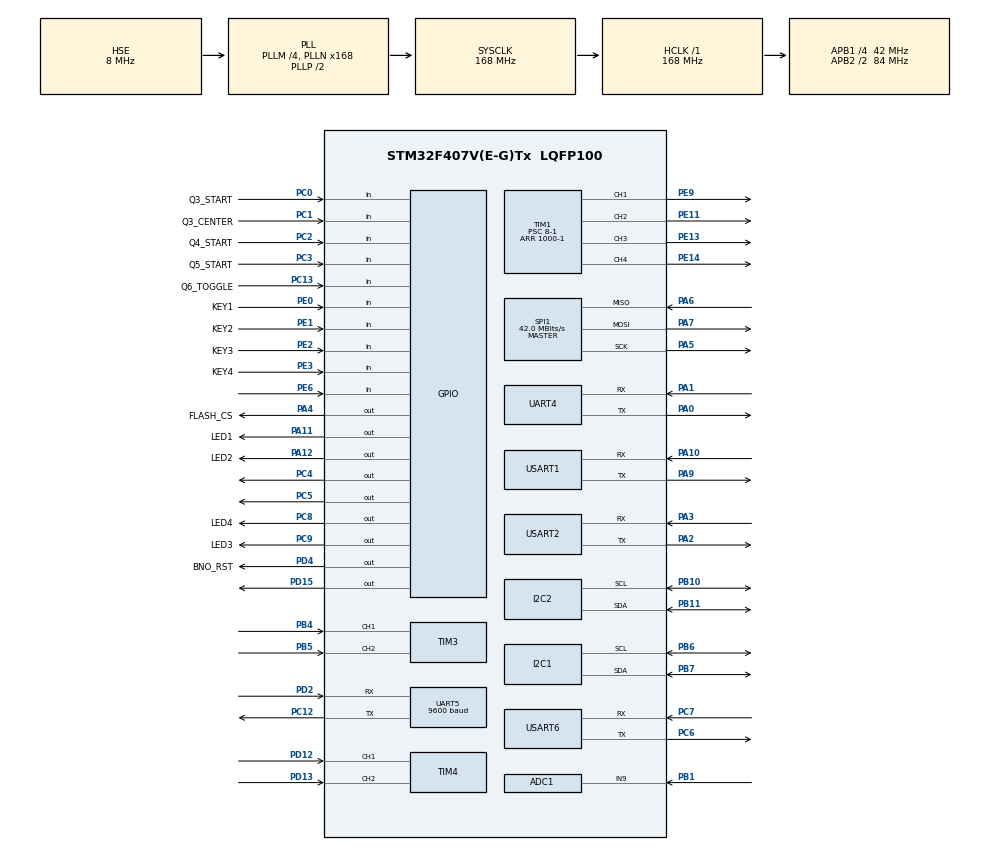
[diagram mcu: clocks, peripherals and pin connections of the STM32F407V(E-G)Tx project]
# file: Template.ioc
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ADC1.Channel-1\#ChannelRegularConversion=ADC_CHANNEL_9
ADC1.NbrOfConversionFlag=1
ADC1.Rank-1\#ChannelRegularConversion=1
ADC1.SamplingTime-1\#ChannelRegularConversion=ADC_SAMPLETIME_144CYCLES
ADC1.master=1
Dma.Request0=UART5_RX
Dma.Request1=USART1_RX
Dma.Request2=USART6_RX
Dma.Request3=UART4_RX
Dma.Request4=USART2_RX
Dma.UART4_RX.3.Direction=DMA_PERIPH_TO_MEMORY
Dma.UART4_RX.3.FIFOMode=DMA_FIFOMODE_DISABLE
Dma.UART4_RX.3.Instance=DMA1_Stream2
Dma.UART4_RX.3.MemDataAlignment=DMA_MDATAALIGN_BYTE
Dma.UART4_RX.3.MemInc=DMA_MINC_ENABLE
Dma.UART4_RX.3.Mode=DMA_NORMAL
Dma.UART4_RX.3.PeriphDataAlignment=DMA_PDATAALIGN_BYTE
Dma.UART4_RX.3.PeriphInc=DMA_PINC_DISABLE
Dma.UART4_RX.3.Priority=DMA_PRIORITY_LOW
Dma.UART5_RX.0.Direction=DMA_PERIPH_TO_MEMORY
Dma.UART5_RX.0.FIFOMode=DMA_FIFOMODE_DISABLE
Dma.UART5_RX.0.Instance=DMA1_Stream0
Dma.UART5_RX.0.MemDataAlignment=DMA_MDATAALIGN_BYTE
Dma.UART5_RX.0.MemInc=DMA_MINC_ENABLE
Dma.UART5_RX.0.Mode=DMA_NORMAL
Dma.UART5_RX.0.PeriphDataAlignment=DMA_PDATAALIGN_BYTE
Dma.UART5_RX.0.PeriphInc=DMA_PINC_DISABLE
Dma.UART5_RX.0.Priority=DMA_PRIORITY_LOW
Dma.USART1_RX.1.Direction=DMA_PERIPH_TO_MEMORY
Dma.USART1_RX.1.FIFOMode=DMA_FIFOMODE_DISABLE
Dma.USART1_RX.1.Instance=DMA2_Stream2
Dma.USART1_RX.1.MemDataAlignment=DMA_MDATAALIGN_BYTE
Dma.USART1_RX.1.MemInc=DMA_MINC_ENABLE
Dma.USART1_RX.1.Mode=DMA_NORMAL
Dma.USART1_RX.1.PeriphDataAlignment=DMA_PDATAALIGN_BYTE
Dma.USART1_RX.1.PeriphInc=DMA_PINC_DISABLE
Dma.USART1_RX.1.Priority=DMA_PRIORITY_LOW
Dma.USART2_RX.4.Direction=DMA_PERIPH_TO_MEMORY
Dma.USART2_RX.4.FIFOMode=DMA_FIFOMODE_DISABLE
Dma.USART2_RX.4.Instance=DMA1_Stream5
Dma.USART2_RX.4.MemDataAlignment=DMA_MDATAALIGN_BYTE
Dma.USART2_RX.4.MemInc=DMA_MINC_ENABLE
Dma.USART2_RX.4.Mode=DMA_NORMAL
Dma.USART2_RX.4.PeriphDataAlignment=DMA_PDATAALIGN_BYTE
Dma.USART2_RX.4.PeriphInc=DMA_PINC_DISABLE
Dma.USART2_RX.4.Priority=DMA_PRIORITY_LOW
Dma.USART6_RX.2.Direction=DMA_PERIPH_TO_MEMORY
Dma.USART6_RX.2.FIFOMode=DMA_FIFOMODE_DISABLE
Dma.USART6_RX.2.Instance=DMA2_Stream1
Dma.USART6_RX.2.MemDataAlignment=DMA_MDATAALIGN_BYTE
Dma.USART6_RX.2.MemInc=DMA_MINC_ENABLE
Dma.USART6_RX.2.Mode=DMA_NORMAL
Dma.USART6_RX.2.PeriphDataAlignment=DMA_PDATAALIGN_BYTE
Dma.USART6_RX.2.PeriphInc=DMA_PINC_DISABLE
Dma.USART6_RX.2.Priority=DMA_PRIORITY_LOW
I2C2.I2C_Mode=I2C_Standard
Mcu.Family=STM32F4
Mcu.Name=STM32F407V(E-G)Tx
Mcu.Package=LQFP100
NVIC.DMA1_Stream0_IRQn=true\:0\:0\:false\:false\:true\:false\:true\:true
NVIC.DMA1_Stream2_IRQn=true\:0\:0\:false\:false\:true\:false\:true\:true
NVIC.DMA1_Stream5_IRQn=true\:0\:0\:false\:false\:true\:false\:true\:true
NVIC.DMA2_Stream1_IRQn=true\:1\:0\:true\:false\:true\:false\:true\:true
NVIC.DMA2_Stream2_IRQn=true\:1\:0\:true\:false\:true\:false\:true\:true
NVIC.PriorityGroup=NVIC_PRIORITYGROUP_4
NVIC.TIM2_IRQn=true\:1\:0\:true\:false\:true\:true\:true\:true
NVIC.UART4_IRQn=true\:1\:0\:true\:false\:true\:true\:true\:true
NVIC.UART5_IRQn=true\:1\:0\:true\:false\:true\:true\:true\:true
NVIC.USART1_IRQn=true\:1\:0\:true\:false\:true\:true\:true\:true
NVIC.USART2_IRQn=true\:1\:0\:true\:false\:true\:true\:true\:true
NVIC.USART6_IRQn=true\:1\:0\:true\:false\:true\:true\:true\:true
PA0.Mode=Asynchronous
PA0.Signal=UART4_TX
PA1.Mode=Asynchronous
PA1.Signal=UART4_RX
PA10.Mode=Asynchronous
PA10.Signal=USART1_RX
PA11.GPIO_Label=LED1
PA11.PinState=GPIO_PIN_SET
PA11.Signal=GPIO_Output
PA12.GPIO_Label=LED2
PA12.PinState=GPIO_PIN_SET
PA12.Signal=GPIO_Output
PA13.Mode=Serial_Wire
PA13.Signal=SYS_JTMS-SWDIO
PA14.Mode=Serial_Wire
PA14.Signal=SYS_JTCK-SWCLK
PA2.Mode=Asynchronous
PA2.Signal=USART2_TX
PA3.Mode=Asynchronous
PA3.Signal=USART2_RX
PA4.GPIO_Label=FLASH_CS
PA4.PinState=GPIO_PIN_SET
PA4.Signal=GPIO_Output
PA5.Mode=Full_Duplex_Master
PA5.Signal=SPI1_SCK
PA6.Mode=Full_Duplex_Master
PA6.Signal=SPI1_MISO
PA7.Mode=Full_Duplex_Master
PA7.Signal=SPI1_MOSI
PA9.Mode=Asynchronous
PA9.Signal=USART1_TX
PB1.Signal=ADCx_IN9
PB10.Mode=I2C
PB10.Signal=I2C2_SCL
PB11.Mode=I2C
PB11.Signal=I2C2_SDA
PB4.Signal=S_TIM3_CH1
PB5.Signal=S_TIM3_CH2
PB6.Mode=I2C
PB6.Signal=I2C1_SCL
PB7.Mode=I2C
PB7.Signal=I2C1_SDA
PC0.GPIO_Label=Q3_START
PC0.GPIO_PuPd=GPIO_PULLUP
PC0.Signal=GPIO_Input
PC1.GPIO_Label=Q3_CENTER
PC1.GPIO_PuPd=GPIO_PULLUP
PC1.Signal=GPIO_Input
PC12.Mode=Asynchronous
PC12.Signal=UART5_TX
PC13-ANTI_TAMP.GPIO_Label=Q6_TOGGLE
PC13-ANTI_TAMP.GPIO_PuPd=GPIO_PULLUP
PC13-ANTI_TAMP.Signal=GPIO_Input
PC14-OSC32_IN.Mode=LSE-External-Oscillator
PC14-OSC32_IN.Signal=RCC_OSC32_IN
PC15-OSC32_OUT.Mode=LSE-External-Oscillator
PC15-OSC32_OUT.Signal=RCC_OSC32_OUT
PC2.GPIO_Label=Q4_START
PC2.GPIO_PuPd=GPIO_PULLUP
PC2.Signal=GPIO_Input
PC3.GPIO_Label=Q5_START
PC3.GPIO_PuPd=GPIO_PULLUP
PC3.Signal=GPIO_Input
PC4.PinState=GPIO_PIN_RESET
PC4.Signal=GPIO_Output
PC5.PinState=GPIO_PIN_RESET
PC5.Signal=GPIO_Output
PC6.Mode=Asynchronous
PC6.Signal=USART6_TX
PC7.Mode=Asynchronous
PC7.Signal=USART6_RX
PC8.GPIO_Label=LED4
PC8.PinState=GPIO_PIN_SET
PC8.Signal=GPIO_Output
PC9.GPIO_Label=LED3
PC9.PinState=GPIO_PIN_SET
PC9.Signal=GPIO_Output
PD12.Signal=S_TIM4_CH1
PD13.Signal=S_TIM4_CH2
PD15.PinState=GPIO_PIN_RESET
PD15.Signal=GPIO_Output
PD2.Mode=Asynchronous
PD2.Signal=UART5_RX
PD4.GPIO_Label=BNO_RST
PD4.Signal=GPIO_Output
PE0.GPIO_Label=KEY1
PE0.Signal=GPIO_Input
PE1.GPIO_Label=KEY2
PE1.Signal=GPIO_Input
PE11.Signal=S_TIM1_CH2
PE13.Signal=S_TIM1_CH3
PE14.Signal=S_TIM1_CH4
PE2.GPIO_Label=KEY3
PE2.Signal=GPIO_Input
PE3.GPIO_Label=KEY4
PE3.Signal=GPIO_Input
PE6.Signal=GPIO_Input
PE9.Signal=S_TIM1_CH1
PH0-OSC_IN.Mode=HSE-External-Oscillator
PH0-OSC_IN.Signal=RCC_OSC_IN
PH1-OSC_OUT.Mode=HSE-External-Oscillator
PH1-OSC_OUT.Signal=RCC_OSC_OUT
ProjectManager.HeapSize=0x1200
ProjectManager.StackSize=0x1000
ProjectManager.TargetToolchain=MDK-ARM V5.32
RCC.48MHZClocksFreq_Value=84000000
RCC.AHBFreq_Value=168000000
RCC.APB1CLKDivider=RCC_HCLK_DIV4
RCC.APB1Freq_Value=42000000
RCC.APB1TimFreq_Value=84000000
RCC.APB2CLKDivider=RCC_HCLK_DIV2
RCC.APB2Freq_Value=84000000
RCC.APB2TimFreq_Value=168000000
RCC.CortexFreq_Value=168000000
RCC.HCLKFreq_Value=168000000
RCC.HSE_VALUE=8000000
RCC.HSI_VALUE=16000000
RCC.PLLM=4
RCC.PLLN=168
RCC.PLLSourceVirtual=RCC_PLLSOURCE_HSE
RCC.SYSCLKFreq_VALUE=168000000
RCC.SYSCLKSource=RCC_SYSCLKSOURCE_PLLCLK
RCC.VCOOutputFreq_Value=336000000
SH.ADCx_IN9.0=ADC1_IN9,IN9
SH.S_TIM1_CH1.0=TIM1_CH1,PWM Generation1 CH1
SH.S_TIM1_CH2.0=TIM1_CH2,PWM Generation2 CH2
SH.S_TIM1_CH3.0=TIM1_CH3,PWM Generation3 CH3
SH.S_TIM1_CH4.0=TIM1_CH4,PWM Generation4 CH4
SH.S_TIM3_CH1.0=TIM3_CH1,Encoder_Interface
SH.S_TIM3_CH2.0=TIM3_CH2,Encoder_Interface
SH.S_TIM4_CH1.0=TIM4_CH1,Encoder_Interface
SH.S_TIM4_CH2.0=TIM4_CH2,Encoder_Interface
SPI1.BaudRatePrescaler=SPI_BAUDRATEPRESCALER_2
SPI1.CLKPhase=SPI_PHASE_2EDGE
SPI1.CLKPolarity=SPI_POLARITY_HIGH
SPI1.CalculateBaudRate=42.0 MBits/s
SPI1.Direction=SPI_DIRECTION_2LINES
SPI1.Mode=SPI_MODE_MASTER
SPI1.VirtualType=VM_MASTER
TIM1.Channel-PWM\ Generation1\ CH1=TIM_CHANNEL_1
TIM1.Channel-PWM\ Generation2\ CH2=TIM_CHANNEL_2
TIM1.Channel-PWM\ Generation3\ CH3=TIM_CHANNEL_3
TIM1.Channel-PWM\ Generation4\ CH4=TIM_CHANNEL_4
TIM1.Period=1000-1
TIM1.Prescaler=8-1
TIM2.Period=1000-1
TIM2.Prescaler=84-1
TIM3.EncoderMode=TIM_ENCODERMODE_TI12
TIM3.IC1Filter=8
TIM3.IC2Filter=8
TIM4.EncoderMode=TIM_ENCODERMODE_TI12
TIM4.IC1Filter=8
TIM4.IC2Filter=8
UART4.VirtualMode=Asynchronous
UART5.BaudRate=9600
UART5.VirtualMode=Asynchronous
USART1.VirtualMode=VM_ASYNC
USART2.VirtualMode=VM_ASYNC
USART6.VirtualMode=VM_ASYNC
VP_TIM1_VS_ClockSourceINT.Mode=Internal
VP_TIM2_VS_ClockSourceINT.Mode=Internal
board=custom

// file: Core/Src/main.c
/* USER CODE BEGIN Header */
/**
  ******************************************************************************
  * @file           : main.c
  * @brief          : Main program body
  ******************************************************************************
  * @attention
  *
  * Copyright (c) 2025 STMicroelectronics.
  * All rights reserved.
  *
  * This software is licensed under terms that can be found in the LICENSE file
  * in the root directory of this software component.
  * If no LICENSE file comes with this software, it is provided AS-IS.
  *
  ******************************************************************************
  */
/* USER CODE END Header */
#include "main.h"
#include "adc.h"
#include "dma.h"
#include "i2c.h"
#include "spi.h"
#include "tim.h"
#include "usart.h"
#include "gpio.h"

/* USER CODE BEGIN Includes */
#include "MyDefine.h"
/* USER CODE END Includes */

void SystemClock_Config(void);

int main(void)
{

  /* MCU Configuration--------------------------------------------------------*/

  /* Reset of all peripherals, Initializes the Flash interface and the Systick. */
  HAL_Init();

  /* Configure the system clock */
  SystemClock_Config();

  /* Initialize all configured peripherals */
  MX_GPIO_Init();
  MX_DMA_Init();
  MX_UART5_Init();
  MX_I2C2_Init();
  MX_TIM1_Init();
  MX_TIM3_Init();
  MX_TIM4_Init();
  MX_TIM2_Init();
  MX_I2C1_Init();
  MX_USART1_UART_Init();
  MX_USART6_UART_Init();
  MX_UART4_Init();
  MX_USART2_UART_Init();
  MX_SPI1_Init();
  MX_ADC1_Init();
  /* USER CODE BEGIN 2 */
  Scheduler_Init();
	System_Init();
  /* USER CODE END 2 */

  /* Infinite loop */
  /* USER CODE BEGIN WHILE */
  while (1)
  {
    Scheduler_Run();
    /* USER CODE END WHILE */

    /* USER CODE BEGIN 3 */
//    Uart_Printf(DEBUG_UART,
//                "Euler Roll=%.2f Pitch=%.2f Yaw=%.2f\r\n",
//                euler_angles.roll,
//                euler_angles.pitch,
//                euler_angles.yaw);
//    HAL_Delay(200);
//		Uart_Printf(&huart5,"{left}%f,%f\r\n",pid_speed_left.target,pid_speed_left.current);
//		Uart_Printf(&huart5,"{right}%f,%f\r\n",pid_speed_right.target,pid_speed_right.current);
  }
  /* USER CODE END 3 */
}

void SystemClock_Config(void)
{
  RCC_OscInitTypeDef RCC_OscInitStruct = {0};
  RCC_ClkInitTypeDef RCC_ClkInitStruct = {0};

  /** Configure the main internal regulator output voltage
  */
  __HAL_RCC_PWR_CLK_ENABLE();
  __HAL_PWR_VOLTAGESCALING_CONFIG(PWR_REGULATOR_VOLTAGE_SCALE1);

  /** Initializes the RCC Oscillators according to the specified parameters
  * in the RCC_OscInitTypeDef structure.
  */
  RCC_OscInitStruct.OscillatorType = RCC_OSCILLATORTYPE_HSE;
  RCC_OscInitStruct.HSEState = RCC_HSE_ON;
  RCC_OscInitStruct.PLL.PLLState = RCC_PLL_ON;
  RCC_OscInitStruct.PLL.PLLSource = RCC_PLLSOURCE_HSE;
  RCC_OscInitStruct.PLL.PLLM = 4;
  RCC_OscInitStruct.PLL.PLLN = 168;
  RCC_OscInitStruct.PLL.PLLP = RCC_PLLP_DIV2;
  RCC_OscInitStruct.PLL.PLLQ = 4;
  if (HAL_RCC_OscConfig(&RCC_OscInitStruct) != HAL_OK)
  {
    Error_Handler();
  }

  /** Initializes the CPU, AHB and APB buses clocks
  */
  RCC_ClkInitStruct.ClockType = RCC_CLOCKTYPE_HCLK|RCC_CLOCKTYPE_SYSCLK
                              |RCC_CLOCKTYPE_PCLK1|RCC_CLOCKTYPE_PCLK2;
  RCC_ClkInitStruct.SYSCLKSource = RCC_SYSCLKSOURCE_PLLCLK;
  RCC_ClkInitStruct.AHBCLKDivider = RCC_SYSCLK_DIV1;
  RCC_ClkInitStruct.APB1CLKDivider = RCC_HCLK_DIV4;
  RCC_ClkInitStruct.APB2CLKDivider = RCC_HCLK_DIV2;

  if (HAL_RCC_ClockConfig(&RCC_ClkInitStruct, FLASH_LATENCY_5) != HAL_OK)
  {
    Error_Handler();
  }
}

void Error_Handler(void)
{
  __disable_irq();
  while (1)
  {
  }
}
